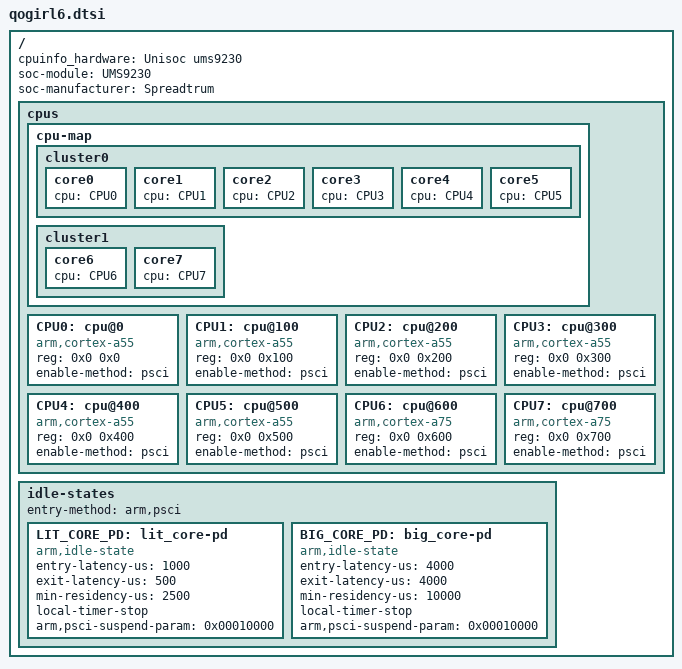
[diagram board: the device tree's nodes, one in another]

/dts-v1/;

/ {
	cpuinfo_hardware = "Unisoc ums9230";
	soc-module = "UMS9230";
	soc-manufacturer = "Spreadtrum";

	cpus {
		#address-cells = <2>;
		#size-cells = <0>;

		cpu-map {
			cluster0 {
				core0 { cpu = <&CPU0>; };
				core1 { cpu = <&CPU1>; };
				core2 { cpu = <&CPU2>; };
				core3 { cpu = <&CPU3>; };
				core4 { cpu = <&CPU4>; };
				core5 { cpu = <&CPU5>; };
			};
			cluster1 {
				core6 { cpu = <&CPU6>; };
				core7 { cpu = <&CPU7>; };
			};
		};

		CPU0: cpu@0 {
			device_type = "cpu";
			compatible = "arm,cortex-a55";
			reg = <0x0 0x0>;
			enable-method = "psci";
		};
		CPU1: cpu@100 {
			device_type = "cpu";
			compatible = "arm,cortex-a55";
			reg = <0x0 0x100>;
			enable-method = "psci";
		};
		CPU2: cpu@200 {
			device_type = "cpu";
			compatible = "arm,cortex-a55";
			reg = <0x0 0x200>;
			enable-method = "psci";
		};
		CPU3: cpu@300 {
			device_type = "cpu";
			compatible = "arm,cortex-a55";
			reg = <0x0 0x300>;
			enable-method = "psci";
		};
		CPU4: cpu@400 {
			device_type = "cpu";
			compatible = "arm,cortex-a55";
			reg = <0x0 0x400>;
			enable-method = "psci";
		};
		CPU5: cpu@500 {
			device_type = "cpu";
			compatible = "arm,cortex-a55";
			reg = <0x0 0x500>;
			enable-method = "psci";
		};
		CPU6: cpu@600 {
			device_type = "cpu";
			compatible = "arm,cortex-a75";
			reg = <0x0 0x600>;
			enable-method = "psci";
		};
		CPU7: cpu@700 {
			device_type = "cpu";
			compatible = "arm,cortex-a75";
			reg = <0x0 0x700>;
			enable-method = "psci";
		};
	};

	idle-states {
		entry-method = "arm,psci";
		LIT_CORE_PD: lit_core-pd {
			compatible = "arm,idle-state";
			entry-latency-us = <1000>;
			exit-latency-us = <500>;
			min-residency-us = <2500>;
			local-timer-stop;
			arm,psci-suspend-param = <0x00010000>;
		};
		BIG_CORE_PD: big_core-pd {
			compatible = "arm,idle-state";
			entry-latency-us = <4000>;
			exit-latency-us = <4000>;
			min-residency-us = <10000>;
			local-timer-stop;
			arm,psci-suspend-param = <0x00010000>;
		};
	};
};
